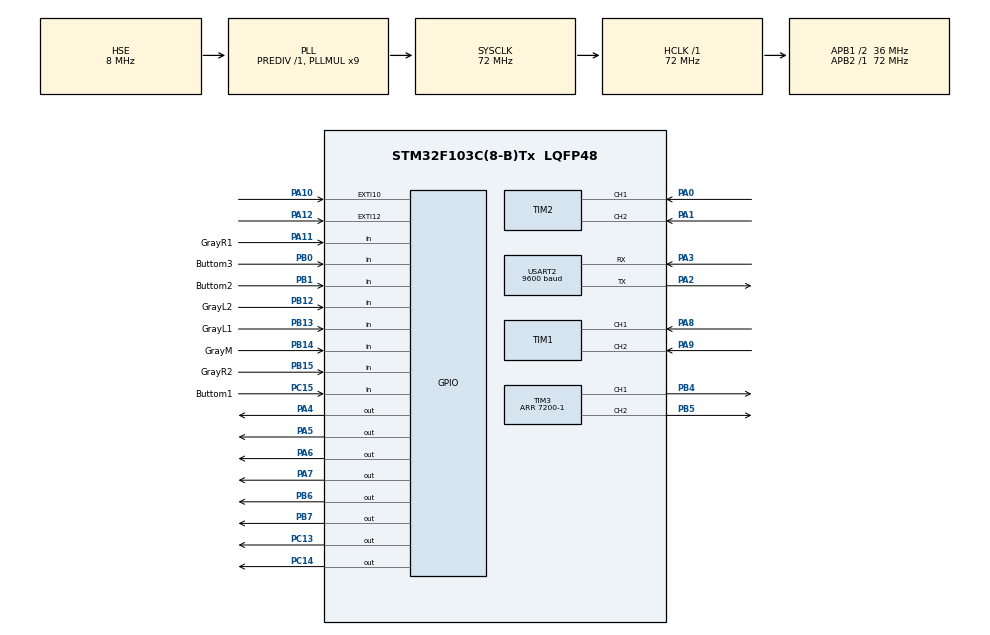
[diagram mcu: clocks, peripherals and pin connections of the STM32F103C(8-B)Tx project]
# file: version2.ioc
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Mcu.Family=STM32F1
Mcu.Name=STM32F103C(8-B)Tx
Mcu.Package=LQFP48
NVIC.EXTI15_10_IRQn=true\:0\:0\:true\:false\:true\:true\:true\:true
NVIC.PriorityGroup=NVIC_PRIORITYGROUP_4
NVIC.TIM4_IRQn=true\:1\:0\:true\:false\:true\:true\:true\:true
NVIC.USART2_IRQn=true\:2\:0\:true\:false\:true\:true\:true\:true
PA0-WKUP.Signal=S_TIM2_CH1_ETR
PA1.Signal=S_TIM2_CH2
PA10.GPIO_ModeDefaultEXTI=GPIO_MODE_IT_FALLING
PA10.GPIO_PuPd=GPIO_PULLUP
PA10.Signal=GPXTI10
PA11.GPIO_Label=GrayR1
PA11.Signal=GPIO_Input
PA12.Signal=GPXTI12
PA13.Mode=Serial_Wire
PA13.Signal=SYS_JTMS-SWDIO
PA14.Mode=Serial_Wire
PA14.Signal=SYS_JTCK-SWCLK
PA2.Mode=Asynchronous
PA2.Signal=USART2_TX
PA3.Mode=Asynchronous
PA3.Signal=USART2_RX
PA4.Signal=GPIO_Output
PA5.Signal=GPIO_Output
PA6.GPIO_ModeDefaultOutputPP=GPIO_MODE_OUTPUT_PP
PA6.GPIO_PuPd=GPIO_NOPULL
PA6.GPIO_Speed=GPIO_SPEED_FREQ_LOW
PA6.PinState=GPIO_PIN_RESET
PA6.Signal=GPIO_Output
PA7.GPIO_ModeDefaultOutputPP=GPIO_MODE_OUTPUT_PP
PA7.GPIO_PuPd=GPIO_NOPULL
PA7.GPIO_Speed=GPIO_SPEED_FREQ_LOW
PA7.PinState=GPIO_PIN_RESET
PA7.Signal=GPIO_Output
PA8.Signal=S_TIM1_CH1
PA9.Signal=S_TIM1_CH2
PB0.GPIO_Label=Buttom3
PB0.GPIO_PuPd=GPIO_PULLUP
PB0.Signal=GPIO_Input
PB1.GPIO_Label=Buttom2
PB1.GPIO_PuPd=GPIO_PULLUP
PB1.Signal=GPIO_Input
PB12.GPIO_Label=GrayL2
PB12.Signal=GPIO_Input
PB13.GPIO_Label=GrayL1
PB13.Signal=GPIO_Input
PB14.GPIO_Label=GrayM
PB14.Signal=GPIO_Input
PB15.GPIO_Label=GrayR2
PB15.Signal=GPIO_Input
PB4.Signal=S_TIM3_CH1
PB5.Signal=S_TIM3_CH2
PB6.Signal=GPIO_Output
PB7.Signal=GPIO_Output
PC13-TAMPER-RTC.GPIO_ModeDefaultOutputPP=GPIO_MODE_OUTPUT_PP
PC13-TAMPER-RTC.GPIO_Speed=GPIO_SPEED_FREQ_HIGH
PC13-TAMPER-RTC.PinState=GPIO_PIN_RESET
PC13-TAMPER-RTC.Signal=GPIO_Output
PC14-OSC32_IN.GPIO_Speed=GPIO_SPEED_FREQ_HIGH
PC14-OSC32_IN.Signal=GPIO_Output
PC15-OSC32_OUT.GPIO_Label=Buttom1
PC15-OSC32_OUT.GPIO_PuPd=GPIO_PULLUP
PC15-OSC32_OUT.Signal=GPIO_Input
PD0-OSC_IN.Mode=HSE-External-Oscillator
PD0-OSC_IN.Signal=RCC_OSC_IN
PD1-OSC_OUT.Mode=HSE-External-Oscillator
PD1-OSC_OUT.Signal=RCC_OSC_OUT
ProjectManager.HeapSize=0x200
ProjectManager.StackSize=0x400
ProjectManager.TargetToolchain=Makefile
RCC.AHBFreq_Value=72000000
RCC.APB1CLKDivider=RCC_HCLK_DIV2
RCC.APB1Freq_Value=36000000
RCC.APB1TimFreq_Value=72000000
RCC.APB2Freq_Value=72000000
RCC.APB2TimFreq_Value=72000000
RCC.HCLKFreq_Value=72000000
RCC.PLLMUL=RCC_PLL_MUL9
RCC.PLLSourceVirtual=RCC_PLLSOURCE_HSE
RCC.SYSCLKFreq_VALUE=72000000
RCC.SYSCLKSource=RCC_SYSCLKSOURCE_PLLCLK
RCC.USBFreq_Value=72000000
SH.S_TIM1_CH1.0=TIM1_CH1,Encoder_Interface
SH.S_TIM1_CH2.0=TIM1_CH2,Encoder_Interface
SH.S_TIM2_CH1_ETR.0=TIM2_CH1,Encoder_Interface
SH.S_TIM2_CH2.0=TIM2_CH2,Encoder_Interface
SH.S_TIM3_CH1.0=TIM3_CH1,PWM Generation1 CH1
SH.S_TIM3_CH2.0=TIM3_CH2,PWM Generation2 CH2
TIM1.EncoderMode=TIM_ENCODERMODE_TI12
TIM1.IC1Filter=5
TIM1.IC2Filter=5
TIM2.EncoderMode=TIM_ENCODERMODE_TI12
TIM2.IC1Filter=5
TIM2.IC2Filter=5
TIM3.AutoReloadPreload=TIM_AUTORELOAD_PRELOAD_ENABLE
TIM3.Channel-PWM\ Generation1\ CH1=TIM_CHANNEL_1
TIM3.Channel-PWM\ Generation2\ CH2=TIM_CHANNEL_2
TIM3.Period=7200-1
TIM4.AutoReloadPreload=TIM_AUTORELOAD_PRELOAD_ENABLE
TIM4.Period=200-1
TIM4.Prescaler=7200-1
USART2.BaudRate=9600
USART2.VirtualMode=VM_ASYNC
VP_TIM3_VS_ClockSourceINT.Mode=Internal
VP_TIM4_VS_ClockSourceINT.Mode=Internal
board=custom

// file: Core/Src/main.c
/* USER CODE BEGIN Header */
/**
  ******************************************************************************
  * @file           : main.c
  * @brief          : Main program body
  ******************************************************************************
  * @attention
  *
  * Copyright (c) 2025 STMicroelectronics.
  * All rights reserved.
  *
  * This software is licensed under terms that can be found in the LICENSE file
  * in the root directory of this software component.
  * If no LICENSE file comes with this software, it is provided AS-IS.
  *
  ******************************************************************************
  */
/* USER CODE END Header */
#include "main.h"
#include "tim.h"
#include "usart.h"
#include "gpio.h"

/* USER CODE BEGIN Includes */
#include "user/start.h"

/* USER CODE END Includes */

void SystemClock_Config(void);

int main(void)
{

  /* MCU Configuration--------------------------------------------------------*/

  /* Reset of all peripherals, Initializes the Flash interface and the Systick. */
  HAL_Init();

  /* Configure the system clock */
  SystemClock_Config();

  /* Initialize all configured peripherals */
  MX_GPIO_Init();
  MX_TIM1_Init();
  MX_TIM2_Init();
  MX_TIM3_Init();
  MX_TIM4_Init();
  MX_USART2_UART_Init();
  /* USER CODE BEGIN 2 */
  startup();
  /* USER CODE END 2 */

  /* Infinite loop */
  while (1)
  {

  }
}

void SystemClock_Config(void)
{
  RCC_OscInitTypeDef RCC_OscInitStruct = {0};
  RCC_ClkInitTypeDef RCC_ClkInitStruct = {0};

  /** Initializes the RCC Oscillators according to the specified parameters
  * in the RCC_OscInitTypeDef structure.
  */
  RCC_OscInitStruct.OscillatorType = RCC_OSCILLATORTYPE_HSE;
  RCC_OscInitStruct.HSEState = RCC_HSE_ON;
  RCC_OscInitStruct.HSEPredivValue = RCC_HSE_PREDIV_DIV1;
  RCC_OscInitStruct.HSIState = RCC_HSI_ON;
  RCC_OscInitStruct.PLL.PLLState = RCC_PLL_ON;
  RCC_OscInitStruct.PLL.PLLSource = RCC_PLLSOURCE_HSE;
  RCC_OscInitStruct.PLL.PLLMUL = RCC_PLL_MUL9;
  if (HAL_RCC_OscConfig(&RCC_OscInitStruct) != HAL_OK)
  {
    Error_Handler();
  }

  /** Initializes the CPU, AHB and APB buses clocks
  */
  RCC_ClkInitStruct.ClockType = RCC_CLOCKTYPE_HCLK|RCC_CLOCKTYPE_SYSCLK
                              |RCC_CLOCKTYPE_PCLK1|RCC_CLOCKTYPE_PCLK2;
  RCC_ClkInitStruct.SYSCLKSource = RCC_SYSCLKSOURCE_PLLCLK;
  RCC_ClkInitStruct.AHBCLKDivider = RCC_SYSCLK_DIV1;
  RCC_ClkInitStruct.APB1CLKDivider = RCC_HCLK_DIV2;
  RCC_ClkInitStruct.APB2CLKDivider = RCC_HCLK_DIV1;

  if (HAL_RCC_ClockConfig(&RCC_ClkInitStruct, FLASH_LATENCY_2) != HAL_OK)
  {
    Error_Handler();
  }
}

void Error_Handler(void)
{
  __disable_irq();
  while (1)
  {
  }
}
